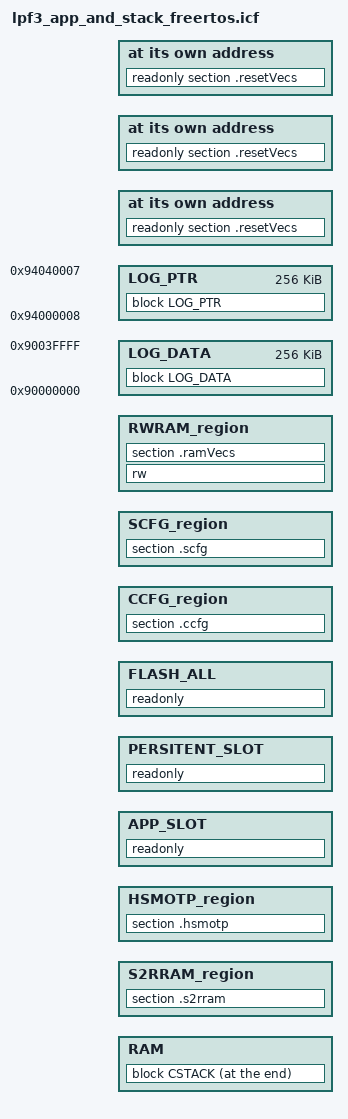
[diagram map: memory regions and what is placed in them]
/******************************************************************************

 @file  lpf3_app_and_stack_freertos.icf

 @brief IAR ARM Linker Configuration File - BLE Application and Stack together

        Imported Symbols
        Note: Linker defines are located in the IAR IDE project using
        --config_def in Options->Linker->Extra Options.

        CCxxxx:             Device Name (e.g. CC2650). In order to define this
                            symbol, the tool chain requires that it be set to
                            a specific value, but in fact, the actual value does
                            not matter as it is not used in the linker control
                            file. The only way this symbol is used is based on
                            whether it is defined or not, not its actual value.
                            There are other linker symbols that do specifically
                            set their value to 1 to indicate R1, and 2 to
                            indicate R2, and these values are checked and do make
                            a difference. However, it would appear confusing if
                            the device name's value did not correspond to the
                            value set in other linker symbols. In order to avoid
                            this confusion, when the symbol is defined, it should
                            be set to the value of the device's ROM that it
                            corresponds so as to look and feel consistent. Please
                            note that a device name symbol should always be
                            defined to avoid side effects from default values
                            that may not be correct for the device being used.

        Exported Symbols
        Note: Can be used as externs in C code.

        PAGE_SIZE: Size of Flash sector, in bytes.
        STACK_TOP: Location of the top of RAM.

 Group: WCS, BTS
 Target Device: cc23xx

 ******************************************************************************
 
 Copyright (c) 2018-2024, Texas Instruments Incorporated
 All rights reserved.

 Redistribution and use in source and binary forms, with or without
 modification, are permitted provided that the following conditions
 are met:

 *  Redistributions of source code must retain the above copyright
    notice, this list of conditions and the following disclaimer.

 *  Redistributions in binary form must reproduce the above copyright
    notice, this list of conditions and the following disclaimer in the
    documentation and/or other materials provided with the distribution.

 *  Neither the name of Texas Instruments Incorporated nor the names of
    its contributors may be used to endorse or promote products derived
    from this software without specific prior written permission.

 THIS SOFTWARE IS PROVIDED BY THE COPYRIGHT HOLDERS AND CONTRIBUTORS "AS IS"
 AND ANY EXPRESS OR IMPLIED WARRANTIES, INCLUDING, BUT NOT LIMITED TO,
 THE IMPLIED WARRANTIES OF MERCHANTABILITY AND FITNESS FOR A PARTICULAR
 PURPOSE ARE DISCLAIMED. IN NO EVENT SHALL THE COPYRIGHT OWNER OR
 CONTRIBUTORS BE LIABLE FOR ANY DIRECT, INDIRECT, INCIDENTAL, SPECIAL,
 EXEMPLARY, OR CONSEQUENTIAL DAMAGES (INCLUDING, BUT NOT LIMITED TO,
 PROCUREMENT OF SUBSTITUTE GOODS OR SERVICES; LOSS OF USE, DATA, OR PROFITS;
 OR BUSINESS INTERRUPTION) HOWEVER CAUSED AND ON ANY THEORY OF LIABILITY,
 WHETHER IN CONTRACT, STRICT LIABILITY, OR TORT (INCLUDING NEGLIGENCE OR
 OTHERWISE) ARISING IN ANY WAY OUT OF THE USE OF THIS SOFTWARE,
 EVEN IF ADVISED OF THE POSSIBILITY OF SUCH DAMAGE.

 ******************************************************************************
 
 
 *****************************************************************************/

include "ti_utils_build_linker.cmd.genmap";
////////////////////////////////////////////////////////////////////////////////
// Memory Sizes
////////////////////////////////////////////////////////////////////////////////
define symbol FLASH_BASE          = ti_utils_build_GenMap_FLASH0_BASE;
if(isdefinedsymbol(SECURE_BOOT))
{
  // Setting an hardcoded flash size is a workaround since the flash size
  // generated in ti_utils_build_linker.cmd.genmap when using Secure Boot
  // is the image size and not the total flash size required in this file.
  define symbol FLASH_SIZE          = 0xE8000;
}
else
{
  define symbol FLASH_SIZE          = ti_utils_build_GenMap_FLASH0_SIZE;
}
define symbol RAM_BASE            = ti_utils_build_GenMap_RAM0_BASE;
define symbol RAM_SIZE            = ti_utils_build_GenMap_RAM0_SIZE;

if (isdefinedsymbol(ti_utils_build_GenMap_S2RRAM_BASE)) {
  define symbol S2RRAM_BASE           = ti_utils_build_GenMap_S2RRAM_BASE;
  define symbol S2RRAM_SIZE           = ti_utils_build_GenMap_S2RRAM_SIZE;
}

define symbol CCFG_BASE           = ti_utils_build_GenMap_CCFG_BASE;
define symbol CCFG_SIZE           = ti_utils_build_GenMap_CCFG_SIZE;

if (isdefinedsymbol(ti_utils_build_GenMap_SCFG_BASE)) {
  define symbol SCFG_BASE           = ti_utils_build_GenMap_SCFG_BASE;
  define symbol SCFG_SIZE           = ti_utils_build_GenMap_SCFG_SIZE;
}

if (isdefinedsymbol(ti_utils_build_GenMap_HSMOTP_BASE)) {
  define symbol HSMOTP_BASE         = ti_utils_build_GenMap_HSMOTP_BASE;
  define symbol HSMOTP_SIZE         = ti_utils_build_GenMap_HSMOTP_SIZE;
}

define symbol NVS_SIZE            = 0x4000;
define symbol NVS_BASE            = (FLASH_SIZE - NVS_SIZE);

if (isdefinedsymbol(OAD_APP_OFFCHIP) || isdefinedsymbol(OAD_APP_ONCHIP) || isdefinedsymbol(OAD_PERSISTENT) || isdefinedsymbol(OAD_DUAL_IMAGE))
{
  if(isdefinedsymbol(SECURE_BOOT))
  {
    define symbol MCU_HDR_SIZE  =  0x80;
    define symbol APP_HDR_BASE  =  APP_HDR_ADDR;
    define symbol APP_BASE      = (APP_HDR_BASE + MCU_HDR_SIZE);
  }
  else
  {
    define symbol MCU_HDR_SIZE  =  0x100;
    define symbol MCUBOOT_BASE  =  FLASH_BASE;
    define symbol MCUBOOT_SIZE  =  0x6000;
    define symbol APP_HDR_BASE  =  APP_HDR_ADDR;
    define symbol APP_BASE      = (APP_HDR_BASE + MCU_HDR_SIZE);
  }
}

if (isdefinedsymbol(OAD_APP_ONCHIP) || isdefinedsymbol(OAD_PERSISTENT))
{
  if(isdefinedsymbol(SECURE_BOOT))
  {
    define symbol PERSISTENT_HDR_BASE  = 0x00;
  }
  else
  {
    define symbol PERSISTENT_HDR_BASE  = 0x6000;
  }
  define symbol PERSISTENT_BASE      = (PERSISTENT_HDR_BASE + MCU_HDR_SIZE);
  define symbol PERSISTENT_SIZE     = (APP_HDR_BASE - PERSISTENT_BASE);
  define symbol APP_SIZE             = (FLASH_SIZE - APP_BASE - NVS_SIZE);
}

if (isdefinedsymbol(OAD_APP_OFFCHIP))
{
  define symbol APP_SIZE      =  (FLASH_SIZE - APP_BASE - NVS_SIZE);
}

if (isdefinedsymbol(OAD_DUAL_IMAGE))
{
  if(isdefinedsymbol(SECURE_BOOT))
  {
    define symbol APP_SIZE      =  ((FLASH_SIZE - NVS_SIZE)/2 - MCU_HDR_SIZE);
  }
  else
  {
    define symbol APP_SIZE      =  ((FLASH_SIZE - NVS_SIZE - MCUBOOT_SIZE)/2 - MCU_HDR_SIZE);
  }
}


////////////////////////////////////////////////////////////////////////////////
// Flash
//
define symbol FLASH_START         = FLASH_BASE;
define symbol FLASH_END           = FLASH_SIZE - NVS_SIZE - 1;
define symbol WORD_SIZE           = 4;
define symbol PAGE_SIZE           = 0x800;
export symbol PAGE_SIZE;

if (isdefinedsymbol(PAGE_ALIGN))
{
  define symbol FLASH_MEM_ALIGN     = PAGE_SIZE;
}
else
{
  define symbol FLASH_MEM_ALIGN     = WORD_SIZE;
}



////////////////////////////////////////////////////////////////////////////////
// Memory Regions and Placments For RAM, S2RRAM, HSMTOP, CCFG, SCFG and Flash
////////////////////////////////////////////////////////////////////////////////

/* Define a memory region that covers the entire 4 GB addressable space */
define memory mem with size          = 4G;

/* Define a region for the SRAM                                         */
define symbol RAM_START           = RAM_BASE;
define symbol RAM_END             = RAM_START+RAM_SIZE-1;
define region RAM                 = mem:[from RAM_START   to RAM_END];

/* Define a Stack top                                                   */
define symbol STACK_SIZE          = 1024;
/* Export stack top symbol. Used by startup file */
define symbol STACK_TOP           = RAM_END + 1;
export symbol STACK_TOP;

define symbol STACK_START          = RAM_END - STACK_SIZE;
export symbol STACK_START;

/* Define a region for the SRAM                                         */
if (isdefinedsymbol(ti_utils_build_GenMap_S2RRAM_BASE)) {
    /* Define a region for the on-chip S2RRAM
     * S2RRAM is intended for the S2R radio module, but it can also be used by the
     * application with some limitations. Please refer to the s2rram example.
     */
    define symbol S2RRAM_START    = S2RRAM_BASE;
    define symbol S2RRAM_END      = S2RRAM_BASE +S2RRAM_SIZE - 1;
    define region S2RRAM_region   = mem:[from S2RRAM_START   to S2RRAM_END];
    /* Placing the section .s2rram in S2RRAM region. Only uninitialized
     * objects may be placed in this section.
     */
    place in S2RRAM_region           { section .s2rram };
    do not initialize                { section .s2rram };
}

/* Define a region for HSMOTP                                           */
if (isdefinedsymbol(ti_utils_build_GenMap_HSMOTP_BASE)) {
  define symbol HSMOTP_START        = HSMOTP_BASE;
  define symbol HSMOTP_END          = HSMOTP_BASE + HSMOTP_SIZE - 1;
  define region HSMOTP_region       = mem:[from HSMOTP_START to HSMOTP_END];

  /* Define a placment for the HSMOTP                                   */
  place in HSMOTP_region             {section .hsmotp};
  keep                               {section .hsmotp};
}

/* Define a region for the flash                                        */
if (isdefinedsymbol(OAD_APP_OFFCHIP) || isdefinedsymbol(OAD_APP_ONCHIP) || isdefinedsymbol(OAD_PERSISTENT) || isdefinedsymbol(OAD_DUAL_IMAGE))
{
  if(!isdefinedsymbol(SECURE_BOOT))
  {
    define region MCUBOOT_SLOT         = mem:[from MCUBOOT_BASE to (MCUBOOT_BASE + MCUBOOT_SIZE)];
  }
  define region APP_HDR_SLOT         = mem:[from APP_HDR_BASE to APP_BASE];
  define region APP_SLOT             = mem:[from APP_BASE to NVS_BASE];

  if (isdefinedsymbol(OAD_APP_ONCHIP) || isdefinedsymbol(OAD_PERSISTENT))
  {
    define region PESISTENT_HDR_SLOT = mem:[from PERSISTENT_HDR_BASE to PERSISTENT_BASE];
    define region PERSITENT_SLOT     = mem:[from PERSISTENT_BASE to APP_HDR_BASE];
  }
}
else
{
  define region FLASH                = mem:[from FLASH_START to FLASH_END];
}

define region FLASH_LAST_PAGE        = mem:[from(FLASH_END) - PAGE_SIZE to FLASH_END-1];
define region FLASH_ALL              = mem:[from FLASH_START to FLASH_END] | FLASH_LAST_PAGE;

/* Define a region for the CCFG                                         */
if (isdefinedsymbol(SECURE_BOOT) || !(isdefinedsymbol(OAD_APP_OFFCHIP) || isdefinedsymbol(OAD_APP_ONCHIP) || isdefinedsymbol(OAD_PERSISTENT) || isdefinedsymbol(OAD_DUAL_IMAGE)))
{
  define symbol CCFG_START          = CCFG_BASE;
  define symbol CCFG_END            = CCFG_BASE + CCFG_SIZE - 1;
  define region CCFG_region         = mem:[from CCFG_START to CCFG_END];

  /* Define a placment for the CCFG                                     */
  place in CCFG_region              {section .ccfg};
  keep                              {section .ccfg};

  /* Define symbols required for CRC32 checksum generation within CCFG and SCFG */
  // The following is used to fix CCFG for Loki PG2

  define exported symbol __ccfg_boot_cfg_crc32_begin    = ti_utils_build_GenMap_CCFG_BASE;
  define exported symbol __ccfg_boot_cfg_crc32_end      = ti_utils_build_GenMap_CCFG_BASE + 0x000B;
  define exported symbol __ccfg_crc32_begin             = ti_utils_build_GenMap_CCFG_BASE + 0x0010;
  define exported symbol __ccfg_crc32_end               = ti_utils_build_GenMap_CCFG_BASE + 0x074B;
  define exported symbol __ccfg_user_record_crc32_begin = ti_utils_build_GenMap_CCFG_BASE + 0x0750;
  define exported symbol __ccfg_user_record_crc32_end   = ti_utils_build_GenMap_CCFG_BASE + 0x07CB;
  define exported symbol __ccfg_debug_cfg_crc32_begin   = ti_utils_build_GenMap_CCFG_BASE + 0x07D0;
  define exported symbol __ccfg_debug_cfg_crc32_end     = ti_utils_build_GenMap_CCFG_BASE + 0x07FB;
  if (isdefinedsymbol(ti_utils_build_GenMap_SCFG_BASE)) {
    define exported symbol __scfg_crc32_begin             = ti_utils_build_GenMap_SCFG_BASE;
    define exported symbol __scfg_crc32_end               = ti_utils_build_GenMap_SCFG_BASE + 0x003B;
  }
}

if (isdefinedsymbol(ti_utils_build_GenMap_SCFG_BASE)) {
  /* Define a region for SCFG                                             */
  define symbol SCFG_START          = SCFG_BASE;
  define symbol SCFG_END            = SCFG_BASE + SCFG_SIZE - 1;
  define region SCFG_region         = mem:[from SCFG_START to SCFG_END];

  /* Define a placment for the CCFG                                     */
  place in SCFG_region 				{section .scfg};
  keep 								{section .scfg };
}

////////////////////////////////////////////////////////////////////////////////
// Memory Placement for other sections
////////////////////////////////////////////////////////////////////////////////

/* Defune a placment for Interrupt Vector Table                          */
if (isdefinedsymbol(OAD_APP_OFFCHIP) || isdefinedsymbol(OAD_APP_ONCHIP) || isdefinedsymbol(OAD_DUAL_IMAGE))
{
  place at address mem:APP_BASE        { readonly section .resetVecs };
}
else if (isdefinedsymbol(OAD_PERSISTENT))
{
  place at address mem:PERSISTENT_BASE { readonly section .resetVecs };
}
else
{
  place at address mem:FLASH_START     { readonly section .resetVecs };
}
keep                                   { readonly section .resetVecs };

// All other pieces of code:
if (isdefinedsymbol(OAD_APP_OFFCHIP) || isdefinedsymbol(OAD_APP_ONCHIP) || isdefinedsymbol(OAD_DUAL_IMAGE))
{
  place in APP_SLOT                    { readonly };
}
else if (isdefinedsymbol(OAD_PERSISTENT))
{
  place in PERSITENT_SLOT              { readonly };
}
else
{
  place in FLASH_ALL                   { readonly };
}

/* Define a placment for CSTACK
 * Define CSTACK block to contain .stack section. This enables the IAR IDE
 * to properly show the stack content during debug. Place stack at end of
 * retention RAM, do not initialize (initializing the stack will destroy the
 * return address from the initialization code, causing the processor to branch
 * to zero and fault)
 */
define block CSTACK with alignment = 8, size = STACK_SIZE { section .stack };

define region RWRAM_region   = mem:[from RAM_START to STACK_START];

/* Define a placment for RWDATA Vector Table                               */
place in RWRAM_region { rw, section .ramVecs };


place at end of RAM { block CSTACK };

////////////////////////////////////////////////////////////////////////////////
// Initialization
////////////////////////////////////////////////////////////////////////////////

initialize by copy { readwrite };

do not initialize
{
  section .ramVecs,
  section .noinit,
  section .stack,
};

////////////////////////////////////////////////////////////////////////////////
// Log data
////////////////////////////////////////////////////////////////////////////////
/* Explicitly placed off target for the storage of logging data.
 * The data placed here is NOT  loaded ont the target device.
 * This is part of 1 GB of external memory from 0x60000000 - 0x9FFFFFFF.
 * ARM memory map can be found here:
 * https://developer.arm.com/documentation/ddi0337/e/memory-map/about-the-memory-map
 */
define region LOG_DATA = mem:[from 0x90000000 to 0x9003FFFF];
define region LOG_PTR = mem:[from 0x94000008 to 0x94040007];
define block LOG_DATA  with size = 0x40000 { readonly section .log_data  };
define block LOG_PTR   with size = 0x40000 { readonly section .log_ptr* };
".log_data": place noload in LOG_DATA { block LOG_DATA };
".log_ptr": place noload in LOG_PTR { block LOG_PTR };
